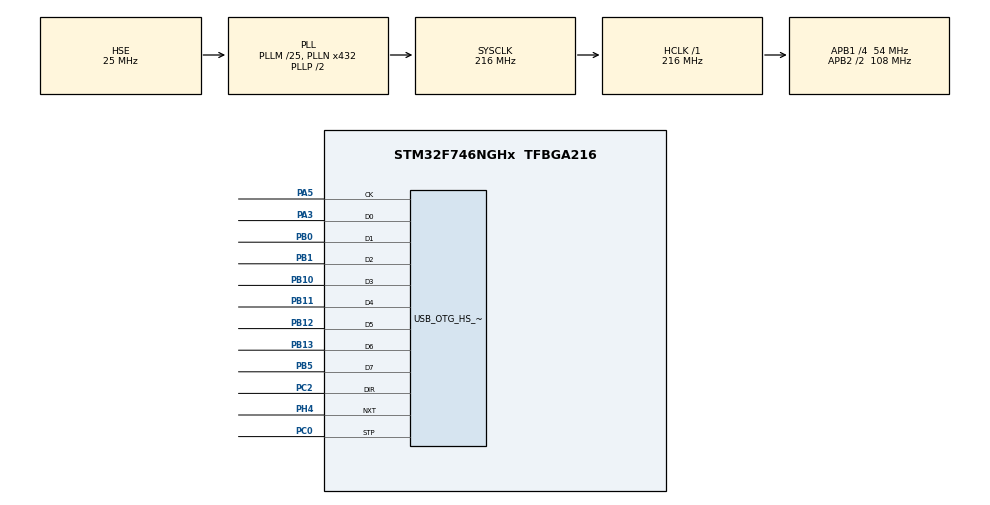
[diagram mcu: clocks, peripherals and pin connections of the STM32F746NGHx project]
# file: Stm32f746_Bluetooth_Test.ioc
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CORTEX_M7.default_mode_Activation=1
Mcu.Family=STM32F7
Mcu.Name=STM32F746NGHx
Mcu.Package=TFBGA216
NVIC.OTG_HS_IRQn=true\:0\:0\:false\:false\:true\:true\:true\:true
NVIC.PriorityGroup=NVIC_PRIORITYGROUP_4
PA13.Mode=Serial_Wire
PA13.Signal=SYS_JTMS-SWDIO
PA14.Mode=Serial_Wire
PA14.Signal=SYS_JTCK-SWCLK
PA3.Mode=Host_HS
PA3.Signal=USB_OTG_HS_ULPI_D0
PA5.Mode=Host_HS
PA5.Signal=USB_OTG_HS_ULPI_CK
PB0.Mode=Host_HS
PB0.Signal=USB_OTG_HS_ULPI_D1
PB1.Mode=Host_HS
PB1.Signal=USB_OTG_HS_ULPI_D2
PB10.Mode=Host_HS
PB10.Signal=USB_OTG_HS_ULPI_D3
PB11.Mode=Host_HS
PB11.Signal=USB_OTG_HS_ULPI_D4
PB12.Mode=Host_HS
PB12.Signal=USB_OTG_HS_ULPI_D5
PB13.Mode=Host_HS
PB13.Signal=USB_OTG_HS_ULPI_D6
PB5.Mode=Host_HS
PB5.Signal=USB_OTG_HS_ULPI_D7
PC0.Mode=Host_HS
PC0.Signal=USB_OTG_HS_ULPI_STP
PC2.Mode=Host_HS
PC2.Signal=USB_OTG_HS_ULPI_DIR
PH0/OSC_IN.Mode=HSE-External-Clock-Source
PH0/OSC_IN.Signal=RCC_OSC_IN
PH1/OSC_OUT.Mode=HSE-External-Clock-Source
PH1/OSC_OUT.Signal=RCC_OSC_OUT
PH4.Mode=Host_HS
PH4.Signal=USB_OTG_HS_ULPI_NXT
ProjectManager.HeapSize=0x2000
ProjectManager.StackSize=0x1000
ProjectManager.TargetToolchain=MDK-ARM V5.32
RCC.AHBFreq_Value=216000000
RCC.APB1CLKDivider=RCC_HCLK_DIV4
RCC.APB1Freq_Value=54000000
RCC.APB1TimFreq_Value=108000000
RCC.APB2CLKDivider=RCC_HCLK_DIV2
RCC.APB2Freq_Value=108000000
RCC.APB2TimFreq_Value=216000000
RCC.CortexFreq_Value=216000000
RCC.HCLKFreq_Value=216000000
RCC.HSE_VALUE=25000000
RCC.HSI_VALUE=16000000
RCC.LSE_VALUE=32768
RCC.PLLM=25
RCC.PLLN=432
RCC.PLLSourceVirtual=RCC_PLLSOURCE_HSE
RCC.SYSCLKFreq_VALUE=216000000
RCC.SYSCLKSource=RCC_SYSCLKSOURCE_PLLCLK
RCC.USBFreq_Value=216000000
RCC.VCOOutputFreq_Value=432000000
USB_HOST.SW_VBUS_DRIVE_HID_HS=true
USB_HOST.USBH_DEBUG_LEVEL-HID_HS=0
USB_HOST.USBH_HandleTypeDef-HID_HS=hUsbHostHS
USB_HOST.USBH_MAX_NUM_ENDPOINTS-HID_HS=8
USB_HOST.USBH_MAX_NUM_INTERFACES-HID_HS=4
USB_HOST.USBH_MAX_SIZE_CONFIGURATION-HID_HS=512
USB_HOST.VirtualModeHS=Hid
USB_OTG_HS.VirtualMode-Host_HS=Host_HS
VP_USB_HOST_VS_USB_HOST_HID_HS.Mode=HID_HS
board=custom

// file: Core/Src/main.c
/* USER CODE BEGIN Header */
/**
  ******************************************************************************
  * @file           : main.c
  * @brief          : Main program body
  ******************************************************************************
  * @attention
  *
  * Copyright (c) 2026 STMicroelectronics.
  * All rights reserved.
  *
  * This software is licensed under terms that can be found in the LICENSE file
  * in the root directory of this software component.
  * If no LICENSE file comes with this software, it is provided AS-IS.
  *
  ******************************************************************************
  */
/* USER CODE END Header */
#include "main.h"
#include "usb_host.h"
#include "gpio.h"

/* USER CODE BEGIN PV */
volatile uint8_t USB_Recognized = 0;

volatile uint16_t USB_VID = 0;
volatile uint16_t USB_PID = 0;

volatile uint8_t USB_Class = 0;
volatile uint8_t USB_SubClass = 0;
volatile uint8_t USB_Protocol = 0;

volatile uint8_t USB_Speed = 0xFF;
/* USER CODE END PV */

void SystemClock_Config(void);
static void MPU_Config(void);
void MX_USB_HOST_Process(void);

int main(void)
{

  /* MPU Configuration--------------------------------------------------------*/
  MPU_Config();

  /* MCU Configuration--------------------------------------------------------*/

  /* Reset of all peripherals, Initializes the Flash interface and the Systick. */
  HAL_Init();

  /* Configure the system clock */
  SystemClock_Config();

  /* Initialize all configured peripherals */
  MX_GPIO_Init();
  MX_USB_HOST_Init();

  /* Infinite loop */
  while (1)
  {

    /* USER CODE BEGIN 3 */
		MX_USB_HOST_Process();
  }
  /* USER CODE END 3 */
}

void SystemClock_Config(void)
{
  RCC_OscInitTypeDef RCC_OscInitStruct = {0};
  RCC_ClkInitTypeDef RCC_ClkInitStruct = {0};

  /** Configure the main internal regulator output voltage
  */
  __HAL_RCC_PWR_CLK_ENABLE();
  __HAL_PWR_VOLTAGESCALING_CONFIG(PWR_REGULATOR_VOLTAGE_SCALE1);

  /** Initializes the RCC Oscillators according to the specified parameters
  * in the RCC_OscInitTypeDef structure.
  */
  RCC_OscInitStruct.OscillatorType = RCC_OSCILLATORTYPE_HSE;
  RCC_OscInitStruct.HSEState = RCC_HSE_BYPASS;
  RCC_OscInitStruct.PLL.PLLState = RCC_PLL_ON;
  RCC_OscInitStruct.PLL.PLLSource = RCC_PLLSOURCE_HSE;
  RCC_OscInitStruct.PLL.PLLM = 25;
  RCC_OscInitStruct.PLL.PLLN = 432;
  RCC_OscInitStruct.PLL.PLLP = RCC_PLLP_DIV2;
  RCC_OscInitStruct.PLL.PLLQ = 2;
  if (HAL_RCC_OscConfig(&RCC_OscInitStruct) != HAL_OK)
  {
    Error_Handler();
  }

  /** Activate the Over-Drive mode
  */
  if (HAL_PWREx_EnableOverDrive() != HAL_OK)
  {
    Error_Handler();
  }

  /** Initializes the CPU, AHB and APB buses clocks
  */
  RCC_ClkInitStruct.ClockType = RCC_CLOCKTYPE_HCLK|RCC_CLOCKTYPE_SYSCLK
                              |RCC_CLOCKTYPE_PCLK1|RCC_CLOCKTYPE_PCLK2;
  RCC_ClkInitStruct.SYSCLKSource = RCC_SYSCLKSOURCE_PLLCLK;
  RCC_ClkInitStruct.AHBCLKDivider = RCC_SYSCLK_DIV1;
  RCC_ClkInitStruct.APB1CLKDivider = RCC_HCLK_DIV4;
  RCC_ClkInitStruct.APB2CLKDivider = RCC_HCLK_DIV2;

  if (HAL_RCC_ClockConfig(&RCC_ClkInitStruct, FLASH_LATENCY_7) != HAL_OK)
  {
    Error_Handler();
  }
}

 /* MPU Configuration */

void MPU_Config(void)
{
  MPU_Region_InitTypeDef MPU_InitStruct = {0};

  /* Disables the MPU */
  HAL_MPU_Disable();

  /** Initializes and configures the Region and the memory to be protected
  */
  MPU_InitStruct.Enable = MPU_REGION_ENABLE;
  MPU_InitStruct.Number = MPU_REGION_NUMBER0;
  MPU_InitStruct.BaseAddress = 0x0;
  MPU_InitStruct.Size = MPU_REGION_SIZE_4GB;
  MPU_InitStruct.SubRegionDisable = 0x87;
  MPU_InitStruct.TypeExtField = MPU_TEX_LEVEL0;
  MPU_InitStruct.AccessPermission = MPU_REGION_NO_ACCESS;
  MPU_InitStruct.DisableExec = MPU_INSTRUCTION_ACCESS_DISABLE;
  MPU_InitStruct.IsShareable = MPU_ACCESS_SHAREABLE;
  MPU_InitStruct.IsCacheable = MPU_ACCESS_NOT_CACHEABLE;
  MPU_InitStruct.IsBufferable = MPU_ACCESS_NOT_BUFFERABLE;

  HAL_MPU_ConfigRegion(&MPU_InitStruct);
  /* Enables the MPU */
  HAL_MPU_Enable(MPU_PRIVILEGED_DEFAULT);

}

void Error_Handler(void)
{
  __disable_irq();
  while (1)
  {
  }
}
